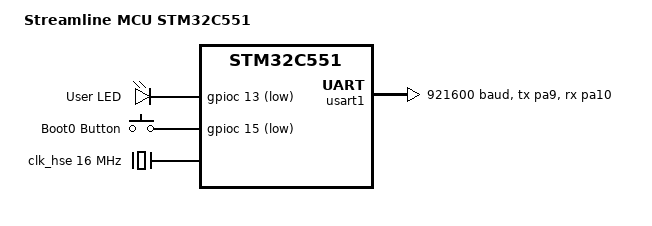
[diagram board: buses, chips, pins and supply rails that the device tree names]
/dts-v1/;
#include <st/c5/stm32c551.dtsi>
#include "streamline_mcu_stm32c551-pinctrl.dtsi"

/ {
	model = "Streamline MCU STM32C551";
	compatible = "currentmakers,streamline-mcu-stm32c551";

	chosen {
		zephyr,sram = &sram1;
		zephyr,flash = &flash0;

		zephyr,console = &usart1;
		zephyr,shell-uart = &usart1;
	};

	leds {
		compatible = "gpio-leds";

		user_led: led_0 {
			gpios = <&gpioc 13 GPIO_ACTIVE_LOW>;
			label = "User LED";
		};
	};

	buttons {
		compatible = "gpio-keys";

		boot_button: button_0 {
			gpios = <&gpioc 15 (GPIO_PULL_UP | GPIO_ACTIVE_LOW)>;
			label = "Boot0 Button";
		};
	};

	aliases {
		led0 = &user_led;
		sw0 = &boot_button;
	};
};

// The sram declaration below might very well be a bug in Zephyr. Should belong in the SOC.
&sram1 {
	reg = <0x20000000 0x10000>; // We might be able to increase that to 128kB, as I think the two memory blocks are contiguous
};

&flash0 {
	reg = <0x08000000 0x80000>; /* 128KB - Adjust to your chip's actual size */
};

/* Configure the External Crystal (HSE) */
&clk_hse {
	clock-frequency = <DT_FREQ_M(16)>; /* SET TO YOUR ACTUAL CRYSTAL FREQ */
	status = "okay";
};

&clk_hsis {
	status = "okay";
};

&rcc {
	clocks = <&clk_hsis>;
	clock-frequency = <DT_FREQ_M(144)>;
	ahb-prescaler = <1>;
	apb1-prescaler = <1>;
	apb2-prescaler = <1>;
	apb3-prescaler = <1>;
};

&usart1 {
	pinctrl-0 = <&usart1_tx_pa9 &usart1_rx_pa10>;
	pinctrl-names = "default";
	current-speed = <921600>;
	status = "okay";
};

